VERSION "Comprehensive CAN DBC File for BMU, CMU, and MPPT"

NS_ :

BU_ :
    ECU_BMU ECU_CMU ECU_MPPT   // BMU: Battery Pack, CMU: Cell Monitoring Units, MPPT: Solar Controllers

// ------------------ BMU DATA ------------------

BO_ 768 BMU_Heartbeat_Sensor: 8 ECU_BMU
    SG_ Device_ID : 0|32@1+ (1,0) [0|4294967295] "ID" ECU_BMU
    SG_ Serial_Number : 32|32@1+ (1,0) [0|4294967295] "Serial" ECU_BMU

BO_ 1012 Pack_SoC: 8 ECU_BMU
    SG_ Pack_SoC : 0|32@1- (1,0) [-1000|1000] "Ah" ECU_BMU
    SG_ Pack_SoC_Percentage : 32|32@1+ (100,0) [0|100] "%" ECU_BMU
SIG_VALTYPE_ 1012 Pack_SoC : 1;
SIG_VALTYPE_ 1012 Pack_SoC_Percentage : 1;

BO_ 1013 Pack_Balance_SoC: 8 ECU_BMU
    SG_ Pack_Balance_SoC : 0|32@1+ (1,0) [0|1000] "Ah" ECU_BMU
    SG_ Pack_Balance_SoC_Percentage : 32|32@1+ (100,0) [0|100] "%" ECU_BMU
SIG_VALTYPE_ 1013 Pack_Balance_SoC : 1;
SIG_VALTYPE_ 1013 Pack_Balance_SoC_Percentage : 1;

BO_ 1018 Battery_Pack_Info: 8 ECU_BMU
    SG_ Pack_Voltage : 0|32@1+ (0.001,0) [0|500] "V" ECU_BMU
    SG_ Pack_Current : 32|32@1- (0.001,0) [-200|200] "A" ECU_BMU

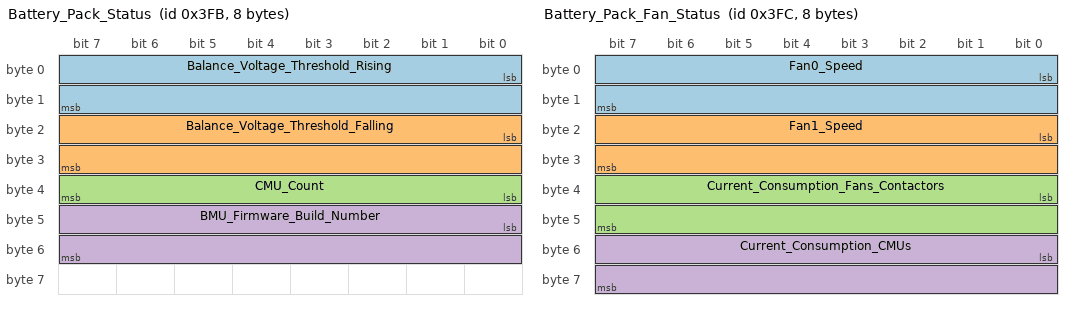
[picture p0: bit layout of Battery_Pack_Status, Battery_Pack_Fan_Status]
BO_ 1019 Battery_Pack_Status: 8 ECU_BMU
    SG_ Balance_Voltage_Threshold_Rising : 0|16@1+ (1,0) [0|5000] "mV" ECU_BMU
    SG_ Balance_Voltage_Threshold_Falling : 16|16@1+ (1,0) [0|5000] "mV" ECU_BMU
    SG_ CMU_Count : 32|8@1+ (1,0) [0|100] "units" ECU_BMU
    SG_ BMU_Firmware_Build_Number : 40|16@1+ (1,0) [0|65535] "Version" ECU_BMU

BO_ 1020 Battery_Pack_Fan_Status: 8 ECU_BMU
    SG_ Fan0_Speed : 0|16@1+ (1,0) [0|5000] "rpm" ECU_BMU
    SG_ Fan1_Speed : 16|16@1+ (1,0) [0|5000] "rpm" ECU_BMU
    SG_ Current_Consumption_Fans_Contactors : 32|16@1+ (0.001,0) [0|50] "A" ECU_BMU
    SG_ Current_Consumption_CMUs : 48|16@1+ (0.001,0) [0|50] "A" ECU_BMU

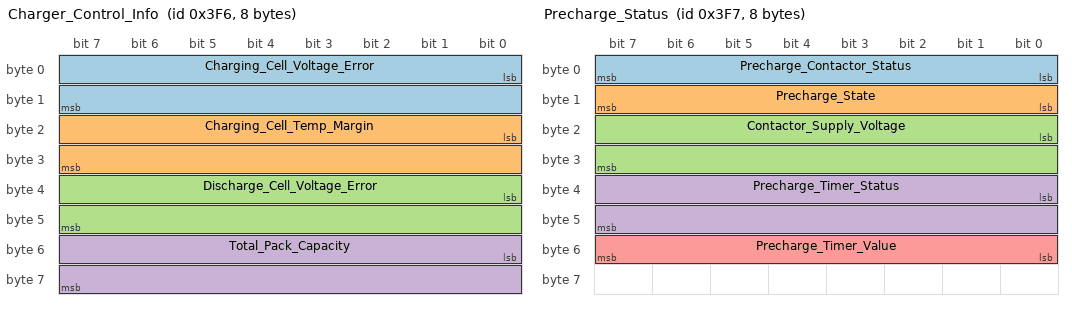
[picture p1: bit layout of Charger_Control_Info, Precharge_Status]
BO_ 1014 Charger_Control_Info: 8 ECU_BMU
    SG_ Charging_Cell_Voltage_Error : 0|16@1+ (1000,0) [0|10000] "mV" ECU_BMU
    SG_ Charging_Cell_Temp_Margin : 16|16@1+ (0.1,0) [-40|125] "°C" ECU_BMU
    SG_ Discharge_Cell_Voltage_Error : 32|16@1+ (1,0) [0|5000] "mV" ECU_BMU
    SG_ Total_Pack_Capacity : 48|16@1+ (1,0) [0|1000] "Ah" ECU_BMU

BO_ 1015 Precharge_Status: 8 ECU_BMU
    SG_ Precharge_Contactor_Status : 0|8@1+ (1,0) [0|255] "bitfield" ECU_BMU
    SG_ Precharge_State : 8|8@1+ (1,0) [0|5] "State" ECU_BMU
    SG_ Contactor_Supply_Voltage : 16|16@1+ (1000,0) [0|10000] "mV" ECU_BMU
    SG_ Precharge_Timer_Status : 32|16@1+ (1,0) [0|65535] "bitfield" ECU_BMU
    SG_ Precharge_Timer_Value : 48|8@1+ (0.01,0) [0|2.55] "s" ECU_BMU

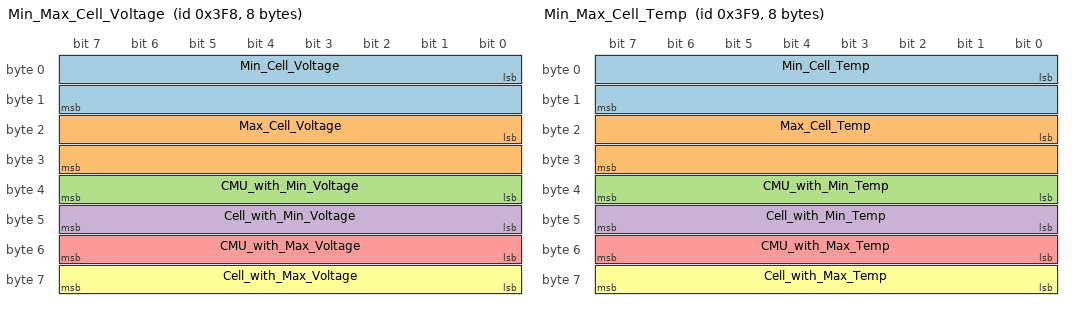
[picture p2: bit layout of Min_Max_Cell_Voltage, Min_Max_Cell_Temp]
BO_ 1016 Min_Max_Cell_Voltage: 8 ECU_BMU
    SG_ Min_Cell_Voltage : 0|16@1+ (0.001,0) [0|5] "V" ECU_BMU
    SG_ Max_Cell_Voltage : 16|16@1+ (0.001,0) [0|5] "V" ECU_BMU
    SG_ CMU_with_Min_Voltage : 32|8@1+ (1,0) [0|255] "ID" ECU_BMU
    SG_ Cell_with_Min_Voltage : 40|8@1+ (1,0) [0|255] "ID" ECU_BMU
    SG_ CMU_with_Max_Voltage : 48|8@1+ (1,0) [0|255] "ID" ECU_BMU
    SG_ Cell_with_Max_Voltage : 56|8@1+ (1,0) [0|255] "ID" ECU_BMU

BO_ 1017 Min_Max_Cell_Temp: 8 ECU_BMU
    SG_ Min_Cell_Temp : 0|16@1+ (0.1,0) [-40|125] "°C" ECU_BMU
    SG_ Max_Cell_Temp : 16|16@1+ (0.1,0) [-40|125] "°C" ECU_BMU
    SG_ CMU_with_Min_Temp : 32|8@1+ (1,0) [0|255] "ID" ECU_BMU
    SG_ Cell_with_Min_Temp : 40|8@1+ (1,0) [0|255] "ID" ECU_BMU
    SG_ CMU_with_Max_Temp : 48|8@1+ (1,0) [0|255] "ID" ECU_BMU
    SG_ Cell_with_Max_Temp : 56|8@1+ (1,0) [0|255] "ID" ECU_BMU

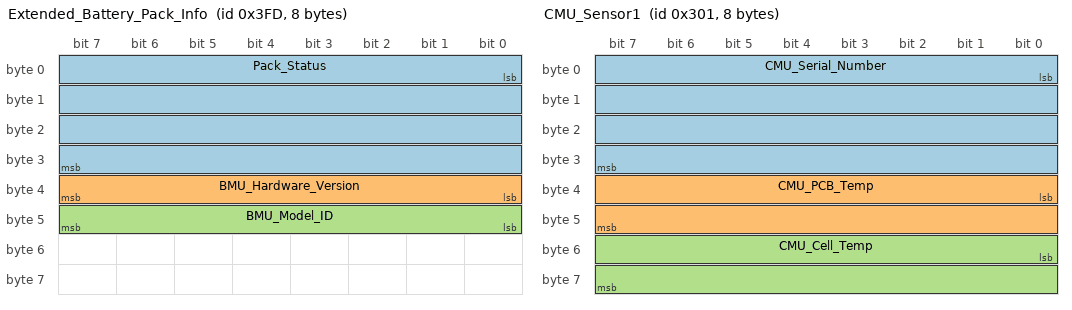
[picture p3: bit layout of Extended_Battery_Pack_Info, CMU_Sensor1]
BO_ 1021 Extended_Battery_Pack_Info: 8 ECU_BMU
    SG_ Pack_Status : 0|32@1+ (1,0) [0|4294967295] "bitfield" ECU_BMU
    SG_ BMU_Hardware_Version : 32|8@1+ (1,0) [0|255] "Version" ECU_BMU
    SG_ BMU_Model_ID : 40|8@1+ (1,0) [0|255] "ID" ECU_BMU
    // The remaining 16 bits reserved

// ------------------ CMU DATA ------------------

// CMU Sensor 1 (IDs 769 - 771)
BO_ 769 CMU_Sensor1: 8 ECU_CMU
    SG_ CMU_Serial_Number : 0|32@1+ (1,0) [0|4294967295] "ID" ECU_CMU
    SG_ CMU_PCB_Temp : 32|16@1+ (0.1,0) [-40|125] "°C" ECU_CMU
    SG_ CMU_Cell_Temp : 48|16@1+ (0.1,0) [-40|125] "°C" ECU_CMU

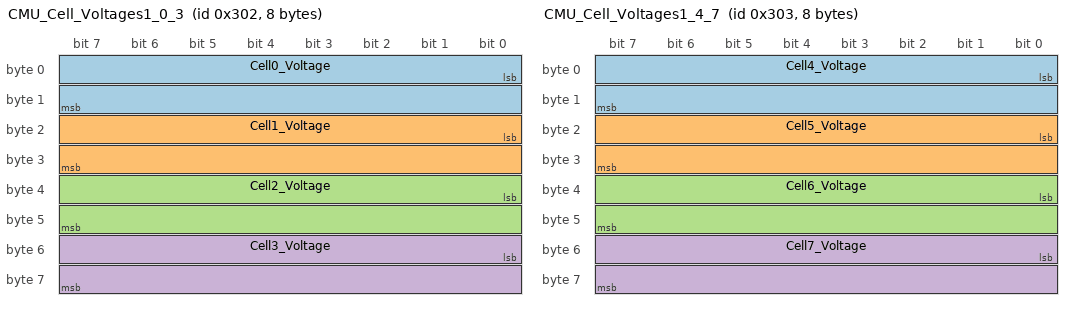
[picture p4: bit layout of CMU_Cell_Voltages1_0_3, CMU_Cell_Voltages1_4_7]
BO_ 770 CMU_Cell_Voltages1_0_3: 8 ECU_CMU
    SG_ Cell0_Voltage : 0|16@1+ (0.001,0) [0|5] "V" ECU_CMU
    SG_ Cell1_Voltage : 16|16@1+ (0.001,0) [0|5] "V" ECU_CMU
    SG_ Cell2_Voltage : 32|16@1+ (0.001,0) [0|5] "V" ECU_CMU
    SG_ Cell3_Voltage : 48|16@1+ (0.001,0) [0|5] "V" ECU_CMU

BO_ 771 CMU_Cell_Voltages1_4_7: 8 ECU_CMU
    SG_ Cell4_Voltage : 0|16@1+ (0.001,0) [0|5] "V" ECU_CMU
    SG_ Cell5_Voltage : 16|16@1+ (0.001,0) [0|5] "V" ECU_CMU
    SG_ Cell6_Voltage : 32|16@1+ (0.001,0) [0|5] "V" ECU_CMU
    SG_ Cell7_Voltage : 48|16@1+ (0.001,0) [0|5] "V" ECU_CMU

// CMU Sensor 2 (IDs 772 - 774)
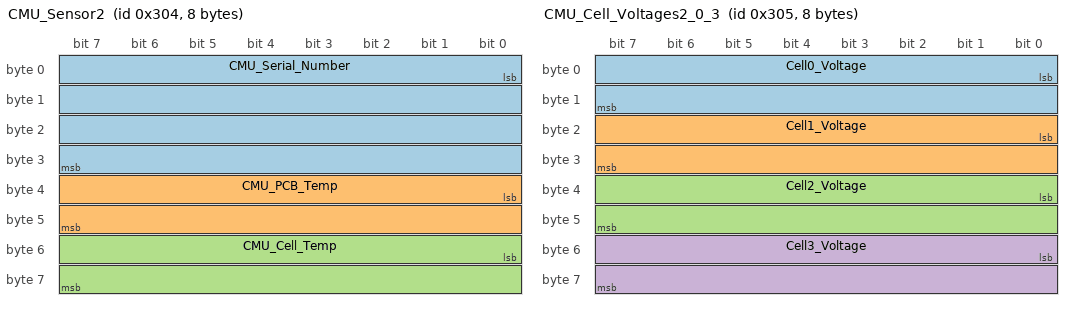
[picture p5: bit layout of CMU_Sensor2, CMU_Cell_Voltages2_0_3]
BO_ 772 CMU_Sensor2: 8 ECU_CMU
    SG_ CMU_Serial_Number : 0|32@1+ (1,0) [0|4294967295] "ID" ECU_CMU
    SG_ CMU_PCB_Temp : 32|16@1+ (0.1,0) [-40|125] "°C" ECU_CMU
    SG_ CMU_Cell_Temp : 48|16@1+ (0.1,0) [-40|125] "°C" ECU_CMU

BO_ 773 CMU_Cell_Voltages2_0_3: 8 ECU_CMU
    SG_ Cell0_Voltage : 0|16@1+ (0.001,0) [0|5] "V" ECU_CMU
    SG_ Cell1_Voltage : 16|16@1+ (0.001,0) [0|5] "V" ECU_CMU
    SG_ Cell2_Voltage : 32|16@1+ (0.001,0) [0|5] "V" ECU_CMU
    SG_ Cell3_Voltage : 48|16@1+ (0.001,0) [0|5] "V" ECU_CMU

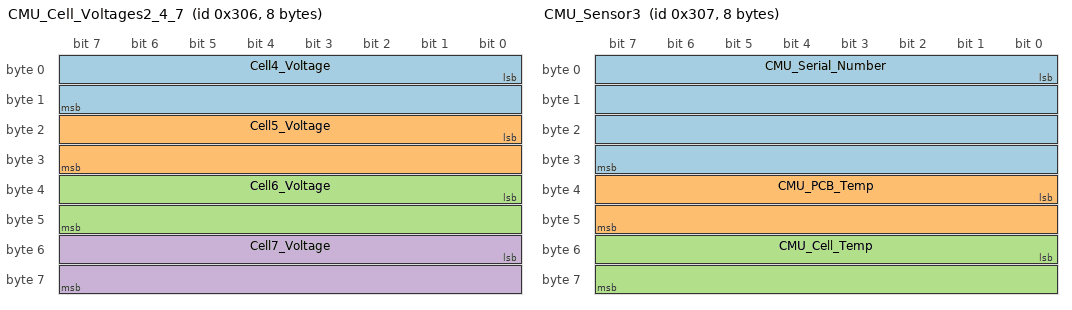
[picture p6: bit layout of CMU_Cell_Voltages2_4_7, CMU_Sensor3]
BO_ 774 CMU_Cell_Voltages2_4_7: 8 ECU_CMU
    SG_ Cell4_Voltage : 0|16@1+ (0.001,0) [0|5] "V" ECU_CMU
    SG_ Cell5_Voltage : 16|16@1+ (0.001,0) [0|5] "V" ECU_CMU
    SG_ Cell6_Voltage : 32|16@1+ (0.001,0) [0|5] "V" ECU_CMU
    SG_ Cell7_Voltage : 48|16@1+ (0.001,0) [0|5] "V" ECU_CMU

// CMU Sensor 3 (IDs 775 - 777)
BO_ 775 CMU_Sensor3: 8 ECU_CMU
    SG_ CMU_Serial_Number : 0|32@1+ (1,0) [0|4294967295] "ID" ECU_CMU
    SG_ CMU_PCB_Temp : 32|16@1+ (0.1,0) [-40|125] "°C" ECU_CMU
    SG_ CMU_Cell_Temp : 48|16@1+ (0.1,0) [-40|125] "°C" ECU_CMU

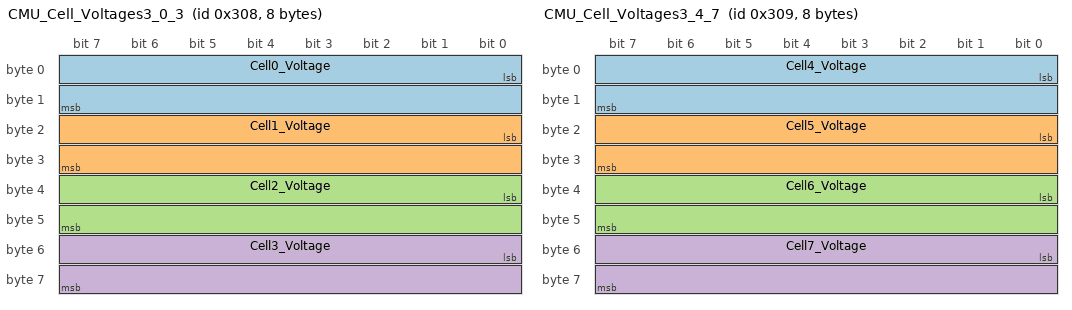
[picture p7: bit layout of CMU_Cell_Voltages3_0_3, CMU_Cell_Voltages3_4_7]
BO_ 776 CMU_Cell_Voltages3_0_3: 8 ECU_CMU
    SG_ Cell0_Voltage : 0|16@1+ (0.001,0) [0|5] "V" ECU_CMU
    SG_ Cell1_Voltage : 16|16@1+ (0.001,0) [0|5] "V" ECU_CMU
    SG_ Cell2_Voltage : 32|16@1+ (0.001,0) [0|5] "V" ECU_CMU
    SG_ Cell3_Voltage : 48|16@1+ (0.001,0) [0|5] "V" ECU_CMU

BO_ 777 CMU_Cell_Voltages3_4_7: 8 ECU_CMU
    SG_ Cell4_Voltage : 0|16@1+ (0.001,0) [0|5] "V" ECU_CMU
    SG_ Cell5_Voltage : 16|16@1+ (0.001,0) [0|5] "V" ECU_CMU
    SG_ Cell6_Voltage : 32|16@1+ (0.001,0) [0|5] "V" ECU_CMU
    SG_ Cell7_Voltage : 48|16@1+ (0.001,0) [0|5] "V" ECU_CMU

// CMU Sensor 4 (IDs 778 - 780)
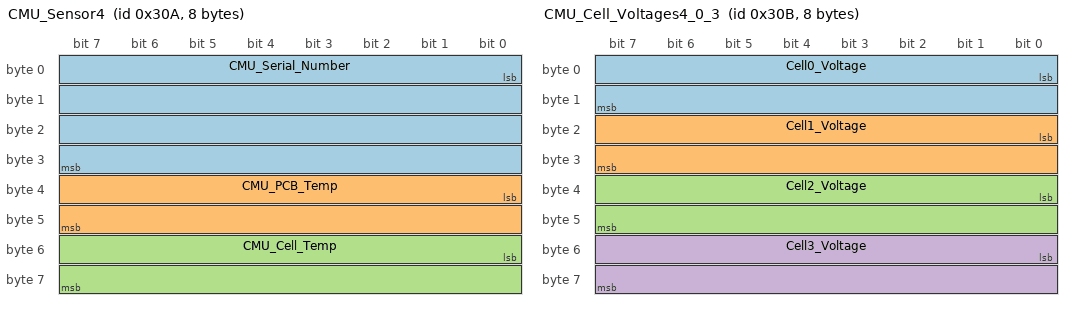
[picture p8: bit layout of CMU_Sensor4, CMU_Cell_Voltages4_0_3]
BO_ 778 CMU_Sensor4: 8 ECU_CMU
    SG_ CMU_Serial_Number : 0|32@1+ (1,0) [0|4294967295] "ID" ECU_CMU
    SG_ CMU_PCB_Temp : 32|16@1+ (0.1,0) [-40|125] "°C" ECU_CMU
    SG_ CMU_Cell_Temp : 48|16@1+ (0.1,0) [-40|125] "°C" ECU_CMU

BO_ 779 CMU_Cell_Voltages4_0_3: 8 ECU_CMU
    SG_ Cell0_Voltage : 0|16@1+ (0.001,0) [0|5] "V" ECU_CMU
    SG_ Cell1_Voltage : 16|16@1+ (0.001,0) [0|5] "V" ECU_CMU
    SG_ Cell2_Voltage : 32|16@1+ (0.001,0) [0|5] "V" ECU_CMU
    SG_ Cell3_Voltage : 48|16@1+ (0.001,0) [0|5] "V" ECU_CMU

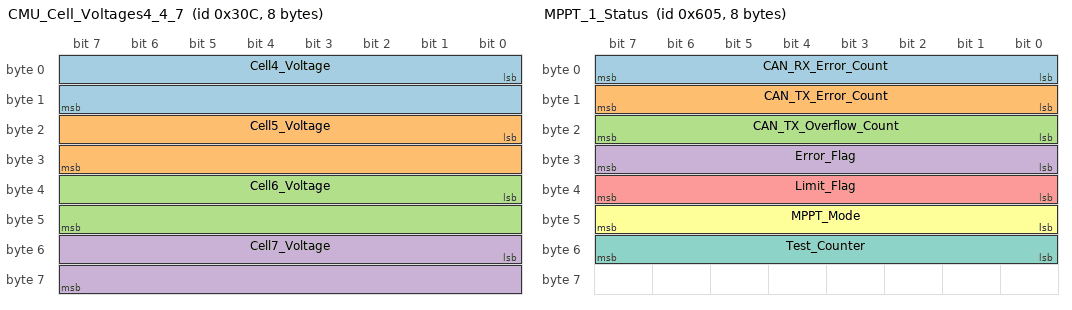
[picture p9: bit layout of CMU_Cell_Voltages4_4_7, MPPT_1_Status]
BO_ 780 CMU_Cell_Voltages4_4_7: 8 ECU_CMU
    SG_ Cell4_Voltage : 0|16@1+ (0.001,0) [0|5] "V" ECU_CMU
    SG_ Cell5_Voltage : 16|16@1+ (0.001,0) [0|5] "V" ECU_CMU
    SG_ Cell6_Voltage : 32|16@1+ (0.001,0) [0|5] "V" ECU_CMU
    SG_ Cell7_Voltage : 48|16@1+ (0.001,0) [0|5] "V" ECU_CMU

// ------------------ MPPT DATA ------------------

//
// MPPT 1 Blocks
//
BO_ 1536 MPPT_1_Input: 8 ECU_MPPT
    SG_ MPPT_Input_Voltage : 0|32@1+ (1, 0) [0|500] "V" ECU_MPPT
    SG_ MPPT_Input_Current : 32|32@1+ (1,0) [0|100] "A" ECU_MPPT
SIG_VALTYPE_ 1536 MPPT_Input_Voltage : 1;
SIG_VALTYPE_ 1536 MPPT_Input_Current : 1;

BO_ 1537 MPPT_1_Output: 8 ECU_MPPT
    SG_ MPPT_Output_Voltage : 0|32@1+ (1,0) [0|500] "V" ECU_MPPT
    SG_ MPPT_Output_Current : 32|32@1+ (1,0) [0|100] "A" ECU_MPPT
SIG_VALTYPE_ 1537 MPPT_Output_Voltage : 1;
SIG_VALTYPE_ 1537 MPPT_Output_Current : 1;

BO_ 1538 MPPT_1_Temperature: 8 ECU_MPPT
    SG_ MOSFET_Temp : 0|32@1+ (1, 0) [-40|125] "°C" ECU_MPPT
    SG_ Controller_Temp : 32|32@1+ (1, 0) [-40|125] "°C" ECU_MPPT
SIG_VALTYPE_ 1538 MOSFET_Temp : 1;
SIG_VALTYPE_ 1538 Controller_Temp : 1;

BO_ 1539 MPPT_1_Aux_Power_Supply: 8 ECU_MPPT
    SG_ Voltage_12V : 0|32@1+ (0.001,0) [0|15] "V" ECU_MPPT
    SG_ Voltage_3V : 32|32@1+ (0.001,0) [0|5] "V" ECU_MPPT

BO_ 1540 MPPT_1_Limits: 8 ECU_MPPT
    SG_ Max_Output_Voltage : 0|32@1+ (0.001,0) [0|500] "V" ECU_MPPT
    SG_ Max_Input_Current : 32|32@1+ (0.001,0) [0|100] "A" ECU_MPPT

BO_ 1541 MPPT_1_Status: 8 ECU_MPPT
    SG_ CAN_RX_Error_Count : 0|8@1+ (1,0) [0|255] "Errors" ECU_MPPT
    SG_ CAN_TX_Error_Count : 8|8@1+ (1,0) [0|255] "Errors" ECU_MPPT
    SG_ CAN_TX_Overflow_Count : 16|8@1+ (1,0) [0|255] "Errors" ECU_MPPT
    SG_ Error_Flag : 24|8@1+ (1,0) [0|255] "Flags" ECU_MPPT
    SG_ Limit_Flag : 32|8@1+ (1,0) [0|255] "Flags" ECU_MPPT
    SG_ MPPT_Mode : 40|8@1+ (1,0) [0|10] "Mode" ECU_MPPT
    SG_ Test_Counter : 48|8@1+ (1,0) [0|255] "Counter" ECU_MPPT

BO_ 1542 MPPT_1_Power_Connector: 8 ECU_MPPT
    SG_ Output_Voltage : 0|32@1+ (0.001,0) [0|500] "V" ECU_MPPT
    SG_ Connector_Temp : 32|32@1+ (0.1,0) [-40|125] "°C" ECU_MPPT

BO_ 1544 MPPT_1_Mode_Send: 8 ECU_MPPT
    SG_ MPPT_Mode_Send : 0|8@1+ (1,0) [0|255] "Mode" ECU_MPPT

BO_ 1546 MPPT_1_Max_Output_Voltage_Send: 8 ECU_MPPT
    SG_ Max_Output_Voltage_Send : 0|32@1+ (0.001,0) [0|500] "V" ECU_MPPT

BO_ 1547 MPPT_1_Max_Input_Current_Send: 8 ECU_MPPT
    SG_ Max_Input_Current_Send : 0|32@1+ (0.001,0) [0|100] "A" ECU_MPPT

//
// MPPT 2 Blocks
//
BO_ 1552 MPPT_2_Input: 8 ECU_MPPT
    SG_ MPPT_Input_Voltage : 0|32@1+ (1,0) [0|500] "V" ECU_MPPT
    SG_ MPPT_Input_Current : 32|32@1+ (1,0) [0|100] "A" ECU_MPPT
SIG_VALTYPE_ 1552 MPPT_Input_Voltage : 1;
SIG_VALTYPE_ 1552 MPPT_Input_Current : 1;

BO_ 1553 MPPT_2_Output: 8 ECU_MPPT
    SG_ MPPT_Output_Voltage : 0|32@1+ (1,0) [0|500] "V" ECU_MPPT
    SG_ MPPT_Output_Current : 32|32@1+ (1,0) [0|100] "A" ECU_MPPT
SIG_VALTYPE_ 1553 MPPT_Output_Voltage : 1;
SIG_VALTYPE_ 1553 MPPT_Output_Current : 1;

BO_ 1554 MPPT_2_Temperature: 8 ECU_MPPT
    SG_ MOSFET_Temp : 0|32@1+ (1,0) [-40|125] "°C" ECU_MPPT
    SG_ Controller_Temp : 32|32@1+ (1,0) [-40|125] "°C" ECU_MPPT
SIG_VALTYPE_ 1554 MOSFET_Temp : 1;
SIG_VALTYPE_ 1554 Controller_Temp : 1;

BO_ 1555 MPPT_2_Aux_Power_Supply: 8 ECU_MPPT
    SG_ Voltage_12V : 0|32@1+ (0.001,0) [0|15] "V" ECU_MPPT
    SG_ Voltage_3V : 32|32@1+ (0.001,0) [0|5] "V" ECU_MPPT

BO_ 1556 MPPT_2_Limits: 8 ECU_MPPT
    SG_ Max_Output_Voltage : 0|32@1+ (0.001,0) [0|500] "V" ECU_MPPT
    SG_ Max_Input_Current : 32|32@1+ (0.001,0) [0|100] "A" ECU_MPPT

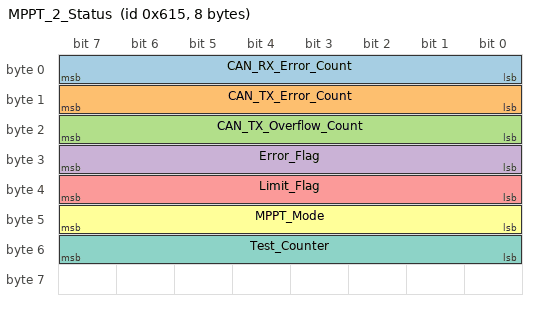
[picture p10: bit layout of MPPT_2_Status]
BO_ 1557 MPPT_2_Status: 8 ECU_MPPT
    SG_ CAN_RX_Error_Count : 0|8@1+ (1,0) [0|255] "Errors" ECU_MPPT
    SG_ CAN_TX_Error_Count : 8|8@1+ (1,0) [0|255] "Errors" ECU_MPPT
    SG_ CAN_TX_Overflow_Count : 16|8@1+ (1,0) [0|255] "Errors" ECU_MPPT
    SG_ Error_Flag : 24|8@1+ (1,0) [0|255] "Flags" ECU_MPPT
    SG_ Limit_Flag : 32|8@1+ (1,0) [0|255] "Flags" ECU_MPPT
    SG_ MPPT_Mode : 40|8@1+ (1,0) [0|10] "Mode" ECU_MPPT
    SG_ Test_Counter : 48|8@1+ (1,0) [0|255] "Counter" ECU_MPPT

BO_ 1558 MPPT_2_Power_Connector: 8 ECU_MPPT
    SG_ Output_Voltage : 0|32@1+ (0.001,0) [0|500] "V" ECU_MPPT
    SG_ Connector_Temp : 32|32@1+ (0.1,0) [-40|125] "°C" ECU_MPPT

BO_ 1560 MPPT_2_Mode_Send: 8 ECU_MPPT
    SG_ MPPT_Mode_Send : 0|8@1+ (1,0) [0|255] "Mode" ECU_MPPT

BO_ 1562 MPPT_2_Max_Output_Voltage_Send: 8 ECU_MPPT
    SG_ Max_Output_Voltage_Send : 0|32@1+ (0.001,0) [0|500] "V" ECU_MPPT

BO_ 1563 MPPT_2_Max_Input_Current_Send: 8 ECU_MPPT
    SG_ Max_Input_Current_Send : 0|32@1+ (0.001,0) [0|100] "A" ECU_MPPT
